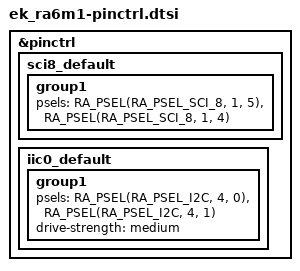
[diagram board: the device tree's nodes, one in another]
/*
 * Copyright (c) 2024 Renesas Electronics Corporation
 * SPDX-License-Identifier: Apache-2.0
 */

&pinctrl {
	sci8_default: sci8_default {
		group1 {
			/* tx rx */
			psels = <RA_PSEL(RA_PSEL_SCI_8, 1, 5)>,
			<RA_PSEL(RA_PSEL_SCI_8, 1, 4)>;
		};
	};

	iic0_default: iic0_default {
		group1 {
			/* SCL0 SDA0 */
			psels = <RA_PSEL(RA_PSEL_I2C, 4, 0)>,
			<RA_PSEL(RA_PSEL_I2C, 4, 1)>;
			drive-strength = "medium";
		};
	};
};
